AUTOSAR XML (schema 4-0-3)
package /ComponentTypes
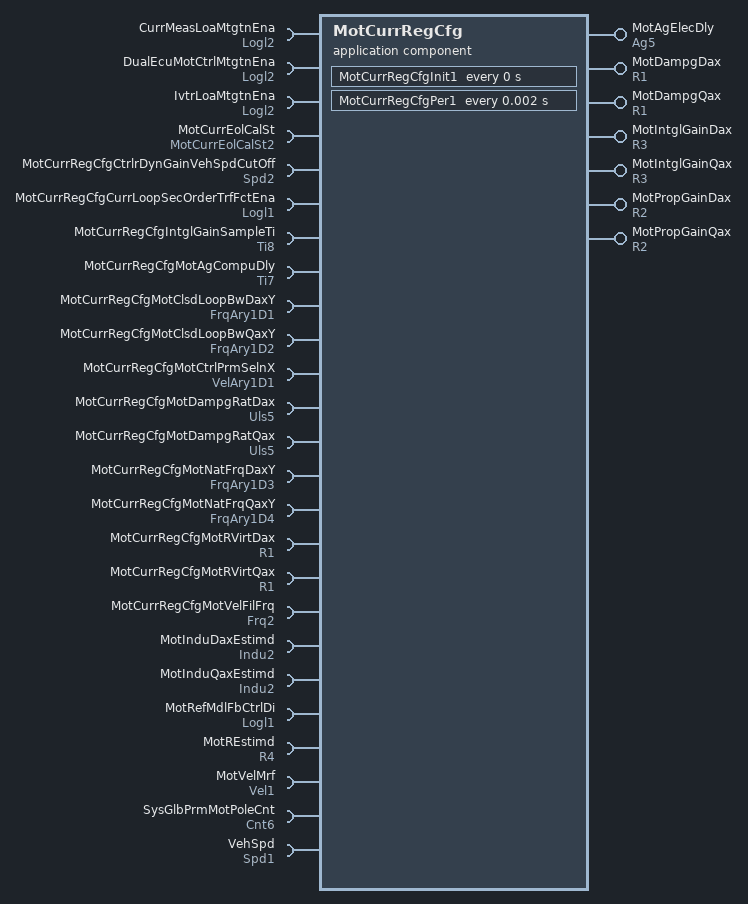
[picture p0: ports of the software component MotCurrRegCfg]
  application sw component type MotCurrRegCfg
    7 x provide port, all with nonqueued-sender-com-spec{data-element=Val, init-value=0}:
      MotAgElecDly: provided-interface=Ag5
      MotDampgDax: provided-interface=R1
      MotDampgQax: provided-interface=R1
      MotIntglGainDax: provided-interface=R3
      MotIntglGainQax: provided-interface=R3
      MotPropGainDax: provided-interface=R2
      MotPropGainQax: provided-interface=R2
    25 x require port:
      CurrMeasLoaMtgtnEna: nonqueued-receiver-com-spec{data-element=Logl, filter=data-filter-type=ALWAYS, init-value=0}, required-interface=Logl2
      DualEcuMotCtrlMtgtnEna: nonqueued-receiver-com-spec{data-element=Logl, filter=data-filter-type=ALWAYS, init-value=0}, required-interface=Logl2
      IvtrLoaMtgtnEna: nonqueued-receiver-com-spec{data-element=Logl, filter=data-filter-type=ALWAYS, init-value=0}, required-interface=Logl2
      MotCurrEolCalSt: nonqueued-receiver-com-spec{data-element=Val, filter=data-filter-type=ALWAYS, init-value=0}, required-interface=MotCurrEolCalSt2
      MotCurrRegCfgCtrlrDynGainVehSpdCutOff: parameter-require-com-spec{init-value=255, parameter=Val}, required-interface=Spd2
      MotCurrRegCfgCurrLoopSecOrderTrfFctEna: parameter-require-com-spec{init-value=1, parameter=Logl}, required-interface=Logl1
      MotCurrRegCfgIntglGainSampleTi: parameter-require-com-spec{init-value=0.000125, parameter=Val}, required-interface=Ti8
      MotCurrRegCfgMotAgCompuDly: parameter-require-com-spec{init-value=0.00009375, parameter=Val}, required-interface=Ti7
      MotCurrRegCfgMotClsdLoopBwDaxY: parameter-require-com-spec{init-value=[200, 300, 300, 300], parameter=Ary1D}, required-interface=FrqAry1D1
      MotCurrRegCfgMotClsdLoopBwQaxY: parameter-require-com-spec{init-value=[200, 300, 300, 300], parameter=Ary1D}, required-interface=FrqAry1D2
      MotCurrRegCfgMotCtrlPrmSelnX: parameter-require-com-spec{init-value=[0, 1, 5, 10], parameter=Ary1D}, required-interface=VelAry1D1
      MotCurrRegCfgMotDampgRatDax: parameter-require-com-spec{init-value=1, parameter=Val}, required-interface=Uls5
      MotCurrRegCfgMotDampgRatQax: parameter-require-com-spec{init-value=1, parameter=Val}, required-interface=Uls5
      MotCurrRegCfgMotNatFrqDaxY: parameter-require-com-spec{init-value=[300, 300, 300, 300], parameter=Ary1D}, required-interface=FrqAry1D3
      MotCurrRegCfgMotNatFrqQaxY: parameter-require-com-spec{init-value=[300, 300, 300, 300], parameter=Ary1D}, required-interface=FrqAry1D4
      MotCurrRegCfgMotRVirtDax: parameter-require-com-spec{init-value=0, parameter=Val}, required-interface=R1
      MotCurrRegCfgMotRVirtQax: parameter-require-com-spec{init-value=0, parameter=Val}, required-interface=R1
      MotCurrRegCfgMotVelFilFrq: parameter-require-com-spec{init-value=10, parameter=Val}, required-interface=Frq2
      MotInduDaxEstimd: nonqueued-receiver-com-spec{data-element=Val, filter=data-filter-type=ALWAYS, init-value=0.00011889}, required-interface=Indu2
      MotInduQaxEstimd: nonqueued-receiver-com-spec{data-element=Val, filter=data-filter-type=ALWAYS, init-value=0.00011889}, required-interface=Indu2
      MotRefMdlFbCtrlDi: parameter-require-com-spec{init-value=0, parameter=Logl}, required-interface=Logl1
      MotREstimd: nonqueued-receiver-com-spec{data-element=Val, filter=data-filter-type=ALWAYS, init-value=0.0139083}, required-interface=R4
      MotVelMrf: nonqueued-receiver-com-spec{data-element=Val, filter=data-filter-type=ALWAYS, init-value=0}, required-interface=Vel1
      SysGlbPrmMotPoleCnt: parameter-require-com-spec{init-value=6, parameter=Val}, required-interface=Cnt6
      VehSpd: nonqueued-receiver-com-spec{data-element=Val, filter=data-filter-type=ALWAYS, init-value=0}, required-interface=Spd1
    behavior MotCurrRegCfg_InternalBehavior: data-type-mapping=Nexteer
      ar-typed-per-instance-memorys:
        data dMotCurrRegCfgMotVelMrfFild: sw-calibration-access=READ-ONLY, type=Vel1
        data MotVelMrfFild: sw-calibration-access=READ-ONLY, type=FilLpRec1
      timing event MotCurrRegCfg_InitEvent: start-on-event=MotCurrRegCfgInit1, period=0
      timing event TMT_MotCurrRegCfgPer1: start-on-event=MotCurrRegCfgPer1, period=0.002
      runnable MotCurrRegCfgInit1
      runnable MotCurrRegCfgPer1
        data-receive-point-by-arguments:
          9 x access:
            REC_DualEcuFltMtgtnEna_Logl: accessed-variable=DualEcuMotCtrlMtgtnEna.Logl
            REC_IvtrLoaMtgtnEna_Logl: accessed-variable=IvtrLoaMtgtnEna.Logl
            REC_MotCurrEolCalSt_Val: accessed-variable=MotCurrEolCalSt.Val
            REC_MotCurrLoaMtgtnEna_Logl: accessed-variable=CurrMeasLoaMtgtnEna.Logl
            REC_MotInduDaxEstimd_Val: accessed-variable=MotInduDaxEstimd.Val
            REC_MotInduQaxEstimd_Val: accessed-variable=MotInduQaxEstimd.Val
            REC_MotREstimd_Val: accessed-variable=MotREstimd.Val
            REC_MotVelMrf_Val: accessed-variable=MotVelMrf.Val
            REC_VehSpd_Val: accessed-variable=VehSpd.Val
        data-send-points:
          7 x access:
            SEND_MotAgElecDly_Val: accessed-variable=MotAgElecDly.Val
            SEND_MotDampgDax_Val: accessed-variable=MotDampgDax.Val
            SEND_MotDampgQax_Val: accessed-variable=MotDampgQax.Val
            SEND_MotIntglGainDax_Val: accessed-variable=MotIntglGainDax.Val
            SEND_MotIntglGainQax_Val: accessed-variable=MotIntglGainQax.Val
            SEND_MotPropGainDax_Val: accessed-variable=MotPropGainDax.Val
            SEND_MotPropGainQax_Val: accessed-variable=MotPropGainQax.Val
  swc implementation MotCurrRegCfg_Implementation: behavior=MotCurrRegCfg_InternalBehavior
    code-descriptors:
      code Default: artifact-descriptors=autosar-engineering-object={short-label=Default, category=SWSRC}
